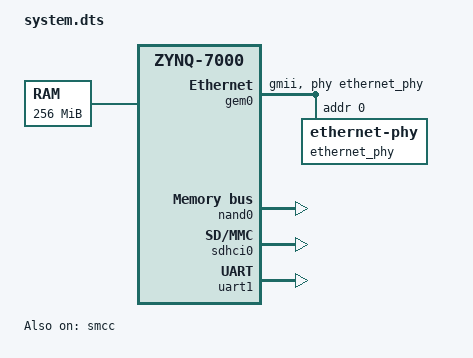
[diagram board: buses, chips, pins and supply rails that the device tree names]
/*
 * CAUTION: This file is automatically generated by Xilinx.
 * Version:  
 * Today is: Mon Feb  8 23:53:23 2021
 */


/dts-v1/;
/include/ "zynq-7000.dtsi"
/ {
	cpus {
		cpu@0 {
			operating-points = <666666 1000000 333333 1000000>;
		};
	};
	chosen {
		bootargs = "earlycon";
		stdout-path = "serial0:115200n8";
	};
	aliases {
		ethernet0 = &gem0;
		serial0 = &uart1;
	};
	memory {
		device_type = "memory";
		reg = <0x0 0x10000000>;
	};
};
&gem0 {
	local-mac-address = [00 0a 35 00 00 00];
	phy-mode = "gmii";
	status = "okay";
	xlnx,ptp-enet-clock = <0x69f6bcb>;
	phy-handle = <&ethernet_phy>;
	
	ethernet_phy: ethernet-phy@0 {
		reg = <0>;
		device_type = "ethernet-phy";
	};
};
&intc {
	num_cpus = <2>;
	num_interrupts = <96>;
};
&nand0 {
	arm,nand-cycle-t0 = <0x4>;
	arm,nand-cycle-t1 = <0x4>;
	arm,nand-cycle-t2 = <0x2>;
	arm,nand-cycle-t3 = <0x2>;
	arm,nand-cycle-t4 = <0x2>;
	arm,nand-cycle-t5 = <0x2>;
	arm,nand-cycle-t6 = <0x4>;
	status = "okay";
	pinctrl-names = "default";

    partition@0 {
        label = "nand-fsbl-uboot";
        reg = <0x0 0x300000>;
    };
    partition@1 {
        label = "nand-linux";
        reg = <0x300000 0x500000>;
    };
    partition@2 {
        label = "nand-device-tree";
        reg = <0x800000 0x20000>;
    };
    partition@3 {
        label = "nand-rootfs";
        reg = <0x820000 0xa00000>;
    };
    partition@4 {
        label = "nand-jffs2";
        reg = <0x1220000 0x1000000>;
    };
    partition@5 {
        label = "nand-bitstream";
        reg = <0x2220000 0x800000>;
    };
    partition@6 {
        label = "nand-allrootfs";
        reg = <0x2a20000 0x4000000>;
    };
    partition@7 {
        label = "nand-release";
        reg = <0x6a20000 0x13e0000>;
    };
    partition@8 {
        label = "nand-reserve";
        reg = <0x7e00000 0x200000>;
    };
};
&sdhci0 {
	status = "okay";
	xlnx,has-cd = <0x0>;
	xlnx,has-power = <0x0>;
	xlnx,has-wp = <0x0>;
};
&smcc {
	status = "okay";
};
&uart1 {
	device_type = "serial";
	port-number = <0>;
	status = "okay";
};
&clkc {
	fclk-enable = <0x1>;
	ps-clk-frequency = <33333333>;
};
